# STM32G0B1 register map
File version: 1.5
CPU: CM0 r0p1, little endian, MPU, no FPU, 4 interrupt priority bits
Registers are 32-bit, read-write, reset 0x0 unless marked. A register's access mark holds for its fields unless they carry their own. Offsets are from the block's base; [hi:lo] are bit positions; {n}, {i} and the like mark numbered series; 'fields as' and 'values as' point back to an identical list.

## DMA1 — Direct memory access controller
Base 0x40020000
Same registers: DMA2 0x40020400
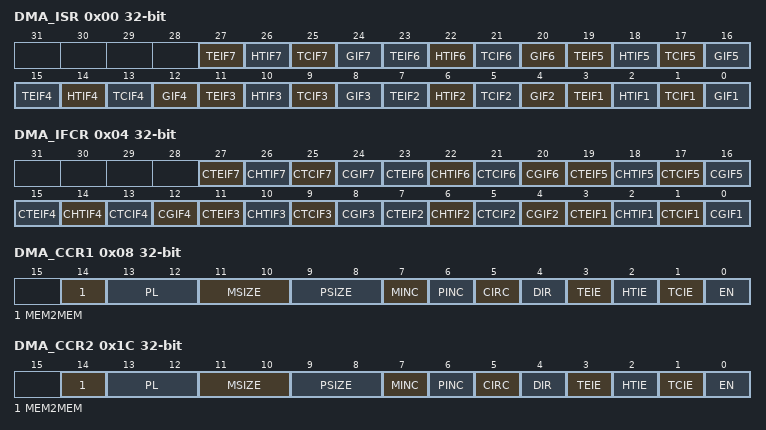
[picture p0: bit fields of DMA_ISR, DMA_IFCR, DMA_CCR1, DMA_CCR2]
0x00 DMA_ISR ro — DMA interrupt status register
  [4n-1] TEIF{n} (n=1..7) — transfer error (TE) flag for channel {n}
    0=no TE event; 1=a TE event occurred
  [4n-2] HTIF{n} (n=1..7) — half transfer (HT) flag for channel {n}
    0=no HT event; 1=a HT event occurred
  [4n-3] TCIF{n} (n=1..7) — transfer complete (TC) flag for channel {n}
    0=no TC event; 1=a TC event occurred
  [4n-4] GIF{n} (n=1..7) — global interrupt flag for channel {n}
    0=no TE, HT or TC event; 1=a TE, HT or TC event occurred
0x04 DMA_IFCR wo — DMA interrupt flag clear register
  [4n-1] CTEIF{n} (n=1..7) — transfer error flag clear for channel {n}
  [4n-2] CHTIF{n} (n=1..7) — half transfer flag clear for channel {n}
  [4n-3] CTCIF{n} (n=1..7) — transfer complete flag clear for channel {n}
  [4n-4] CGIF{n} (n=1..7) — global interrupt flag clear for channel {n}
0x08 DMA_CCR1 — DMA channel 1 configuration register
  [14] MEM2MEM — memory-to-memory mode Note: this bit is set and cleared by software. It must not be written when the channel is enabled (EN = 1). It is read-only when the channel is enabled (EN = 1).
    0=disabled; 1=enabled
  [13:12] PL — priority level Note: this field is set and cleared by software. It must not be written when the channel is enabled (EN = 1). It is read-only when the channel is enabled (EN = 1).
    0=low; 1=medium; 2=high; 3=very high
  [11:10] MSIZE — memory size Defines the data size of each DMA transfer to the identified memory. In memory-to-memory mode, this field identifies the memory source if DIR = 1 and the memory destination if DIR = 0. In peripheral-to-peripheral mode, this field identifies the peripheral source if DIR = 1 and the peripheral destination if DIR = 0. Note: this field is set and cleared by software. It must not be written when the channel is enabled (EN = 1). It is read-only when the channel is enabled (EN = 1).
    0=8 bits; 1=16 bits; 2=32 bits
  [9:8] PSIZE — peripheral size Defines the data size of each DMA transfer to the identified peripheral. In memory-to-memory mode, this field identifies the memory destination if DIR = 1 and the memory source if DIR = 0. In peripheral-to-peripheral mode, this field identifies the peripheral destination if DIR = 1 and the peripheral source if DIR = 0. Note: this field is set and cleared by software. It must not be written when the channel is enabled (EN = 1). It is read-only when the channel is enabled (EN = 1).
    0=8 bits; 1=16 bits; 2=32 bits
  [7] MINC — memory increment mode Defines the increment mode for each DMA transfer to the identified memory. In memory-to-memory mode, this field identifies the memory source if DIR = 1 and the memory destination if DIR = 0. In peripheral-to-peripheral mode, this field identifies the peripheral source if DIR = 1 and the peripheral destination if DIR = 0. Note: this bit is set and cleared by software. It must not be written when the channel is enabled (EN = 1). It is read-only when the channel is enabled (EN = 1).
    0=disabled; 1=enabled
  [6] PINC — peripheral increment mode Defines the increment mode for each DMA transfer to the identified peripheral. n memory-to-memory mode, this field identifies the memory destination if DIR = 1 and the memory source if DIR = 0. In peripheral-to-peripheral mode, this field identifies the peripheral destination if DIR = 1 and the peripheral source if DIR = 0. Note: this bit is set and cleared by software. It must not be written when the channel is enabled (EN = 1). It is read-only when the channel is enabled (EN = 1).
    0=disabled; 1=enabled
  [5] CIRC — circular mode Note: this bit is set and cleared by software. It must not be written when the channel is enabled (EN = 1). It is not read-only when the channel is enabled (EN = 1).
    0=disabled; 1=enabled
  [4] DIR — data transfer direction This bit must be set only in memory-to-peripheral and peripheral-to-memory modes. Source attributes are defined by PSIZE and PINC, plus the DMA_CPARx register. This is still valid in a memory-to-memory mode. Destination attributes are defined by MSIZE and MINC, plus the DMA_CMARx register. This is still valid in a peripheral-to-peripheral mode. Destination attributes are defined by PSIZE and PINC, plus the DMA_CPARx register. This is still valid in a memory-to-memory mode. Source attributes are defined by MSIZE and MINC, plus the DMA_CMARx register. This is still valid in a peripheral-to-peripheral mode. Note: this bit is set and cleared by software. It must not be written when the channel is enabled (EN = 1). It is read-only when the channel is enabled (EN = 1).
    0=read from peripheral; 1=read from memory
  [3] TEIE — transfer error interrupt enable Note: this bit is set and cleared by software. It must not be written when the channel is enabled (EN = 1). It is not read-only when the channel is enabled (EN = 1).
    0=disabled; 1=enabled
  [2] HTIE — half transfer interrupt enable Note: this bit is set and cleared by software. It must not be written when the channel is enabled (EN = 1). It is not read-only when the channel is enabled (EN = 1).
    0=disabled; 1=enabled
  [1] TCIE — transfer complete interrupt enable Note: this bit is set and cleared by software. It must not be written when the channel is enabled (EN = 1). It is not read-only when the channel is enabled (EN = 1).
    0=disabled; 1=enabled
  [0] EN — channel enable When a channel transfer error occurs, this bit is cleared by hardware. It can not be set again by software (channel x re-activated) until the TEIFx bit of the DMA_ISR register is cleared (by setting the CTEIFx bit of the DMA_IFCR register). Note: this bit is set and cleared by software.
    0=disabled; 1=enabled
0x0C DMA_CNDTR1 — DMA channel 1 number of data to transfer register
  [15:0] NDT — number of data to transfer (0 to 216 - 1) This field is updated by hardware when the channel is enabled: It is decremented after each single DMA 'read followed by write' transfer, indicating the remaining amount of data items to transfer. It is kept at zero when the programmed amount of data to transfer is reached, if the channel is not in circular mode (CIRC = 0 in the DMA_CCRx register). It is reloaded automatically by the previously programmed value, when the transfer is complete, if the channel is in circular mode (CIRC = 1). If this field is zero, no transfer can be served whatever the channel status (enabled or not). Note: this field is set and cleared by software. It must not be written when the channel is enabled (EN = 1). It is read-only when the channel is enabled (EN = 1).
0x10 DMA_CPAR1 — DMA channel 1 peripheral address register
  [31:0] PA — peripheral address It contains the base address of the peripheral data register from/to which the data will be read/written. When PSIZE[1:0] = 01 (16 bits), bit 0 of PA[31:0] is ignored. Access is automatically aligned to a half-word address. When PSIZE = 10 (32 bits), bits 1 and 0 of PA[31:0] are ignored. Access is automatically aligned to a word address. In memory-to-memory mode, this register identifies the memory destination address if DIR = 1 and the memory source address if DIR = 0. In peripheral-to-peripheral mode, this register identifies the peripheral destination address DIR = 1 and the peripheral source address if DIR = 0. Note: this register is set and cleared by software. It must not be written when the channel is enabled (EN = 1). It is not read-only when the channel is enabled (EN = 1).
{0x0+0x14*i} DMA_CMAR{i} (i=1..7) — DMA channel {i} memory address register
  [31:0] MA — peripheral address It contains the base address of the memory from/to which the data will be read/written. When MSIZE[1:0] = 01 (16 bits), bit 0 of MA[31:0] is ignored. Access is automatically aligned to a half-word address. When MSIZE = 10 (32 bits), bits 1 and 0 of MA[31:0] are ignored. Access is automatically aligned to a word address. In memory-to-memory mode, this register identifies the memory source address if DIR = 1 and the memory destination address if DIR = 0. In peripheral-to-peripheral mode, this register identifies the peripheral source address DIR = 1 and the peripheral destination address if DIR = 0. Note: this register is set and cleared by software. It must not be written when the channel is enabled (EN = 1). It is not read-only when the channel is enabled (EN = 1).
0x1C DMA_CCR2 — DMA channel 2 configuration register
  fields as DMA_CCR1
0x20 DMA_CNDTR2 — DMA channel 2 number of data to transfer register
  fields as DMA_CNDTR1
0x24 DMA_CPAR2 — DMA channel 2 peripheral address register
  fields as DMA_CPAR1
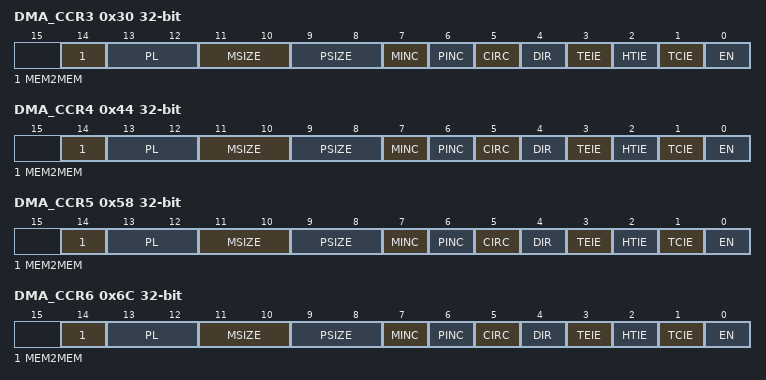
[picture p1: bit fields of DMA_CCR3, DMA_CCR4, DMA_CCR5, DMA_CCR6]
0x30 DMA_CCR3 — DMA channel 3 configuration register
  fields as DMA_CCR1
0x34 DMA_CNDTR3 — DMA channel 3 number of data to transfer register
  fields as DMA_CNDTR1
0x38 DMA_CPAR3 — DMA channel 3 peripheral address register
  fields as DMA_CPAR1
0x44 DMA_CCR4 — DMA channel 4 configuration register
  fields as DMA_CCR1
0x48 DMA_CNDTR4 — DMA channel 4 number of data to transfer register
  fields as DMA_CNDTR1
0x4C DMA_CPAR4 — DMA channel 4 peripheral address register
  fields as DMA_CPAR1
0x58 DMA_CCR5 — DMA channel 5 configuration register
  fields as DMA_CCR1
0x5C DMA_CNDTR5 — DMA channel 5 number of data to transfer register
  fields as DMA_CNDTR1
0x60 DMA_CPAR5 — DMA channel 5 peripheral address register
  fields as DMA_CPAR1
0x6C DMA_CCR6 — DMA channel 6 configuration register
  fields as DMA_CCR1
0x70 DMA_CNDTR6 — DMA channel 6 number of data to transfer register
  fields as DMA_CNDTR1
0x74 DMA_CPAR6 — DMA channel 6 peripheral address register
  fields as DMA_CPAR1
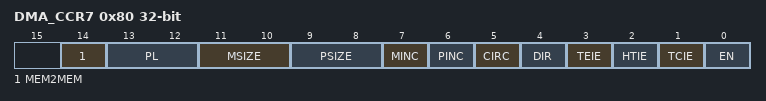
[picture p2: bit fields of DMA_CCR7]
0x80 DMA_CCR7 — DMA channel 7 configuration register
  fields as DMA_CCR1
0x84 DMA_CNDTR7 — DMA channel 7 number of data to transfer register
  fields as DMA_CNDTR1
0x88 DMA_CPAR7 — DMA channel 7 peripheral address register
  fields as DMA_CPAR1
